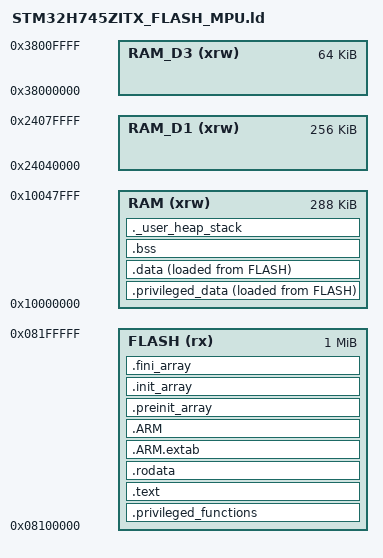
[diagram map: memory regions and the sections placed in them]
/*
******************************************************************************
**
**  File        : LinkerScript.ld
**
**  Author      : STM32CubeIDE
**
**  Abstract    : Linker script for STM32H7 series
**                1024Kbytes FLASH and 288Kbytes RAM
**
**                Set heap size, stack size and stack location according
**                to application requirements.
**
**                Set memory bank area and size if external memory is used.
**
**  Target      : STMicroelectronics STM32
**
**  Distribution: The file is distributed as is, without any warranty
**                of any kind.
**
*****************************************************************************
** @attention
**
** <h2><center>&copy; Copyright (c) 2021 STMicroelectronics.
** All rights reserved.</center></h2>
**
** This software component is licensed by ST under BSD 3-Clause license,
** the "License"; You may not use this file except in compliance with the
** License. You may obtain a copy of the License at:
**                        opensource.org/licenses/BSD-3-Clause
**
****************************************************************************
*/

/* Entry Point */
ENTRY(Reset_Handler)

/* Highest address of the user mode stack */
_estack = ORIGIN(RAM) + LENGTH(RAM); /* end of RAM */
/* Generate a link error if heap and stack don't fit into RAM */
_Min_Heap_Size = 0x200 ;      /* required amount of heap  */
_Min_Stack_Size = 0x400 ; /* required amount of stack */

/* Specify the memory areas */
MEMORY
{
FLASH (rx)     : ORIGIN = 0x08100000, LENGTH = 1024K
RAM (xrw)      : ORIGIN = 0x10000000, LENGTH = 288K
RAM_D1 (xrw)   : ORIGIN = 0x24040000, LENGTH = 256K
RAM_D3 (xrw)   : ORIGIN = 0x38000000, LENGTH = 64K
}


/* Initial 32K Flash is used to store kernel functions and
 * initial 32K RAM is used to store kernel data. */
__privileged_functions_region_size__  = 32K;
__privileged_data_region_size__       = 32K;

__FLASH_segment_start__               = ORIGIN( FLASH );
__FLASH_segment_end__                 = __FLASH_segment_start__ + LENGTH( FLASH );

__SRAM_segment_start__                = ORIGIN( RAM );
__SRAM_segment_end__                  = __SRAM_segment_start__ + LENGTH( RAM );

__privileged_functions_start__        = __FLASH_segment_start__;
__privileged_functions_end__          = __FLASH_segment_start__ + __privileged_functions_region_size__;

__privileged_data_start__             = __SRAM_segment_start__;
__privileged_data_end__               = __SRAM_segment_start__ + __privileged_data_region_size__;



/* Define output sections */
SECTIONS
{
  /* The startup code goes first into FLASH */



/* The startup code and FreeRTOS kernel code are placed into privileged
   * flash. */
  .privileged_functions :
  {
    . = ALIGN(4);
    KEEP(*(.isr_vector)) /* Startup code. */
    . = ALIGN(4);
    *(privileged_functions)
    . = ALIGN(4);
    FILL(0xDEAD);
    /* Ensure that non-privileged code is placed after the region reserved for
     * privileged kernel code. */
    /* Note that dot (.) actually refers to the byte offset from the start of
     * the current section (.privileged_functions in this case). As a result,
     * setting dot (.) to a value sets the size of the section. */
    . = __privileged_functions_region_size__;
  } >FLASH


  /* The program code and other data into "FLASH" Rom type memory */
  .text :
  {
    /* Place the FreeRTOS System Calls first in the unprivileged region. */
    . = ALIGN(4);
    __syscalls_flash_start__ = .;
    *(freertos_system_calls)
    __syscalls_flash_end__ = .;
    . = ALIGN(4);
    *(.text)           /* .text sections (code) */
    *(.text*)          /* .text* sections (code) */
    *(.glue_7)         /* glue arm to thumb code */
    *(.glue_7t)        /* glue thumb to arm code */
    *(.eh_frame)

    KEEP (*(.init))
    KEEP (*(.fini))

    . = ALIGN(4);
    _etext = .;        /* define a global symbols at end of code */
  } >FLASH



  /* Constant data goes into FLASH */
  .rodata :
  {
    . = ALIGN(4);
    *(.rodata)         /* .rodata sections (constants, strings, etc.) */
    *(.rodata*)        /* .rodata* sections (constants, strings, etc.) */
    . = ALIGN(4);
  } >FLASH

  .ARM.extab   : { *(.ARM.extab* .gnu.linkonce.armextab.*) } >FLASH
  .ARM : {
    __exidx_start = .;
    *(.ARM.exidx*)
    __exidx_end = .;
  } >FLASH

  .preinit_array     :
  {
    PROVIDE_HIDDEN (__preinit_array_start = .);
    KEEP (*(.preinit_array*))
    PROVIDE_HIDDEN (__preinit_array_end = .);
  } >FLASH
  .init_array :
  {
    PROVIDE_HIDDEN (__init_array_start = .);
    KEEP (*(SORT(.init_array.*)))
    KEEP (*(.init_array*))
    PROVIDE_HIDDEN (__init_array_end = .);
  } >FLASH
  .fini_array :
  {
    PROVIDE_HIDDEN (__fini_array_start = .);
    KEEP (*(SORT(.fini_array.*)))
    KEEP (*(.fini_array*))
    PROVIDE_HIDDEN (__fini_array_end = .);
  } >FLASH

  /* used by the startup to initialize data */
 _sidata = LOADADDR(.privileged_data);
  
  
   /* FreeRTOS kernel data. */
  .privileged_data :
  {
    . = ALIGN(4);
    _sdata = .;        /* Create a global symbol at data start. */
    *(privileged_data)
    . = ALIGN(4);
    FILL(0xDEAD);
    /* Ensure that non-privileged data is placed after the region reserved for
     * privileged kernel data. */
    /* Note that dot (.) actually refers to the byte offset from the start of
     * the current section (.privileged_data in this case). As a result, setting
     * dot (.) to a value sets the size of the section. */
    . = __privileged_data_region_size__;
  } >RAM AT> FLASH
  
  
  /* Initialized data sections goes into RAM, load LMA copy after code */
  .data :
  {
    . = ALIGN(4);
    *(.data)           /* .data sections */
    *(.data*)          /* .data* sections */
    *(.RamFunc)        /* .RamFunc sections */
    *(.RamFunc*)       /* .RamFunc* sections */

    . = ALIGN(4);
    _edata = .;        /* define a global symbol at data end */
  } >RAM AT> FLASH

  
  
  /* Uninitialized data section */
  . = ALIGN(4);
  .bss :
  {
    /* This is used by the startup in order to initialize the .bss secion */
    _sbss = .;         /* define a global symbol at bss start */
    __bss_start__ = _sbss;
    *(.bss)
    *(.bss*)
    *(COMMON)

    . = ALIGN(4);
    _ebss = .;         /* define a global symbol at bss end */
    __bss_end__ = _ebss;
  } >RAM

  /* User_heap_stack section, used to check that there is enough RAM left */
  ._user_heap_stack :
  {
    . = ALIGN(8);
    PROVIDE ( end = . );
    PROVIDE ( _end = . );
    . = . + _Min_Heap_Size;
    . = . + _Min_Stack_Size;
    . = ALIGN(8);
  } >RAM



  /* Remove information from the standard libraries */
  /DISCARD/ :
  {
    libc.a ( * )
    libm.a ( * )
    libgcc.a ( * )
  }

  .ARM.attributes 0 : { *(.ARM.attributes) }
}


